# HDSC_HC32L072FAUA register map
Vendor: HDSC Co.Ltd; Series: ARMCM0P; File version: 1.2
CPU: CM0 r0p0, little endian, no MPU, no FPU, 3 interrupt priority bits
Registers are 32-bit, read-write, reset 0x0 unless marked. A register's access mark holds for its fields unless they carry their own. Offsets are from the block's base; [hi:lo] are bit positions; {n}, {i} and the like mark numbered series.

## ADTIM4 — desc ADTIM
Base 0x40003000
Same registers: ADTIM5 0x40003400, ADTIM6 0x40003800
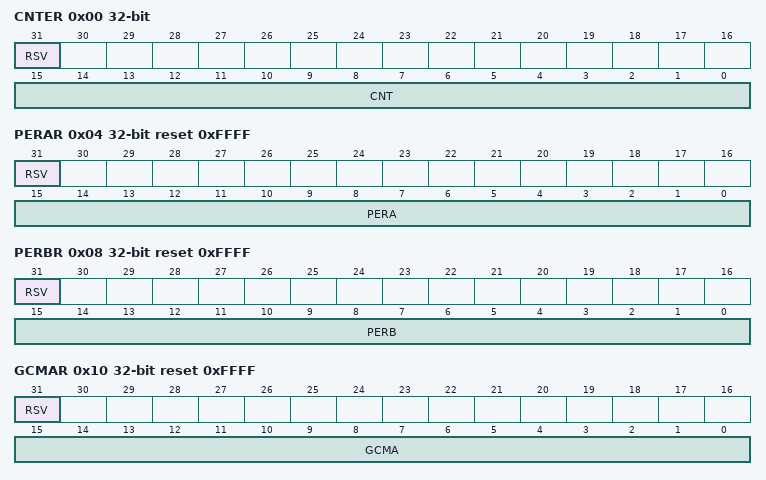
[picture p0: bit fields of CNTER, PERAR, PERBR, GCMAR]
0x00 CNTER (reset mask 0xFFFF)
  [31] RSV, [15:0] CNT
0x04 PERAR reset 0xFFFF (reset mask 0xFFFF)
  [31] RSV, [15:0] PERA
0x08 PERBR reset 0xFFFF (reset mask 0xFFFF)
  [31] RSV, [15:0] PERB
0x10 GCMAR reset 0xFFFF (reset mask 0xFFFF)
  [31] RSV, [15:0] GCMA
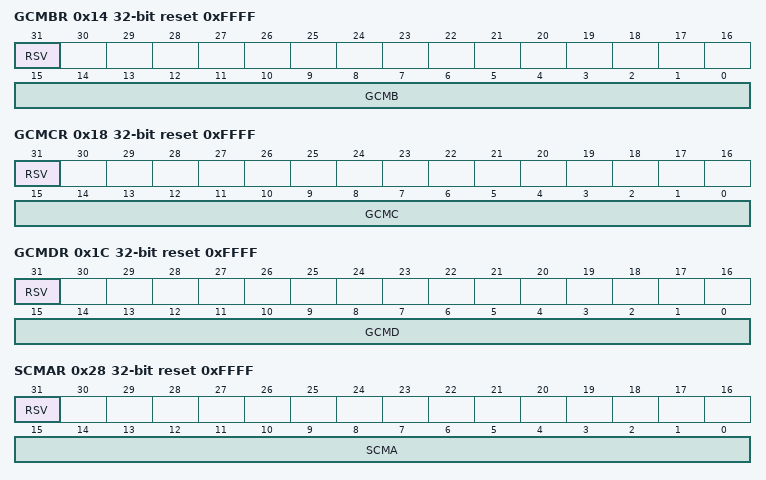
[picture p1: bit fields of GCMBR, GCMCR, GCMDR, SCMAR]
0x14 GCMBR reset 0xFFFF (reset mask 0xFFFF)
  [31] RSV, [15:0] GCMB
0x18 GCMCR reset 0xFFFF (reset mask 0xFFFF)
  [31] RSV, [15:0] GCMC
0x1C GCMDR reset 0xFFFF (reset mask 0xFFFF)
  [31] RSV, [15:0] GCMD
0x28 SCMAR reset 0xFFFF (reset mask 0xFFFF)
  [31] RSV, [15:0] SCMA
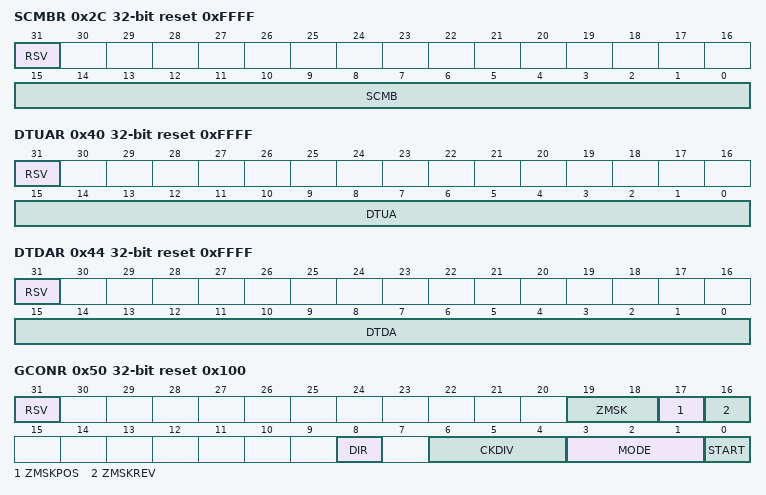
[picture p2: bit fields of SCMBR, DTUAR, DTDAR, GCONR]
0x2C SCMBR reset 0xFFFF (reset mask 0xFFFF)
  [31] RSV, [15:0] SCMB
0x40 DTUAR reset 0xFFFF (reset mask 0xFFFF)
  [31] RSV, [15:0] DTUA
0x44 DTDAR reset 0xFFFF (reset mask 0xFFFF)
  [31] RSV, [15:0] DTDA
0x50 GCONR reset 0x100 (reset mask 0xF017F)
  [31] RSV, [19:18] ZMSK, [17] ZMSKPOS, [16] ZMSKREV, [8] DIR, [6:4] CKDIV, [3:1] MODE, [0] START
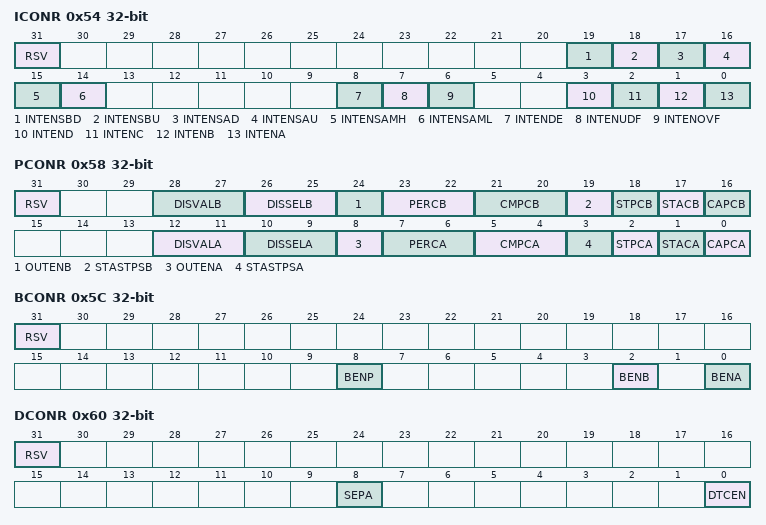
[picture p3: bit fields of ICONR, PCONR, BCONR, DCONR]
0x54 ICONR (reset mask 0xFC1CF)
  [31] RSV, [19] INTENSBD, [18] INTENSBU, [17] INTENSAD, [16] INTENSAU, [15] INTENSAMH, [14] INTENSAML, [8] INTENDE, [7] INTENUDF, [6] INTENOVF, [3] INTEND, [2] INTENC, [1] INTENB, [0] INTENA
0x58 PCONR (reset mask 0x1FFF1FFF)
  [31] RSV, [28:27] DISVALB, [26:25] DISSELB, [24] OUTENB, [23:22] PERCB, [21:20] CMPCB, [19] STASTPSB, [18] STPCB, [17] STACB, [16] CAPCB, [12:11] DISVALA, [10:9] DISSELA, [8] OUTENA, [7:6] PERCA, [5:4] CMPCA, [3] STASTPSA, [2] STPCA, [1] STACA, [0] CAPCA
0x5C BCONR (reset mask 0x105)
  [31] RSV, [8] BENP, [2] BENB, [0] BENA
0x60 DCONR (reset mask 0x101)
  [31] RSV, [8] SEPA, [0] DTCEN
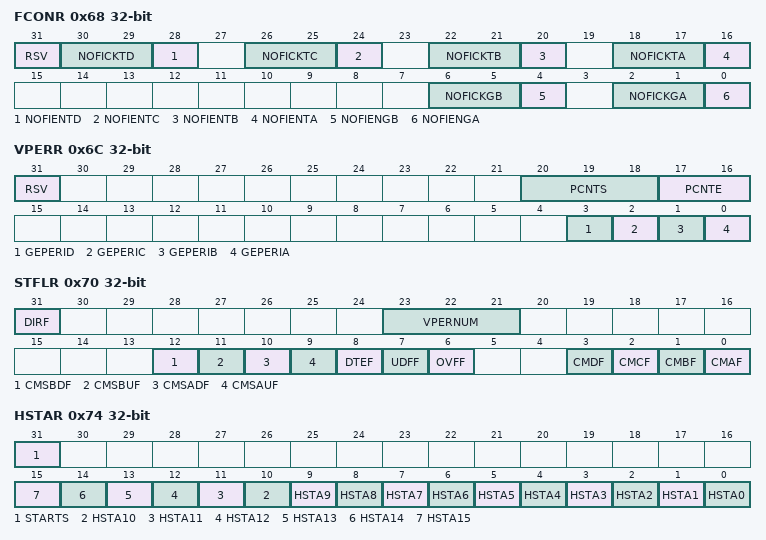
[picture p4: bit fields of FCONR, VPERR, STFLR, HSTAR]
0x68 FCONR (reset mask 0x77770077)
  [31] RSV, [30:29] NOFICKTD, [28] NOFIENTD, [26:25] NOFICKTC, [24] NOFIENTC, [22:21] NOFICKTB, [20] NOFIENTB, [18:17] NOFICKTA, [16] NOFIENTA, [6:5] NOFICKGB, [4] NOFIENGB, [2:1] NOFICKGA, [0] NOFIENGA
0x6C VPERR (reset mask 0x1F000F)
  [31] RSV, [20:18] PCNTS, [17:16] PCNTE, [3] GEPERID, [2] GEPERIC, [1] GEPERIB, [0] GEPERIA
0x70 STFLR
  [31] DIRF ro, [23:21] VPERNUM ro, [12] CMSBDF, [11] CMSBUF, [10] CMSADF, [9] CMSAUF, [8] DTEF, [7] UDFF, [6] OVFF, [3] CMDF, [2] CMCF, [1] CMBF, [0] CMAF
0x74 HSTAR
  [31] STARTS, [n] HSTA{n} (n=0..15)
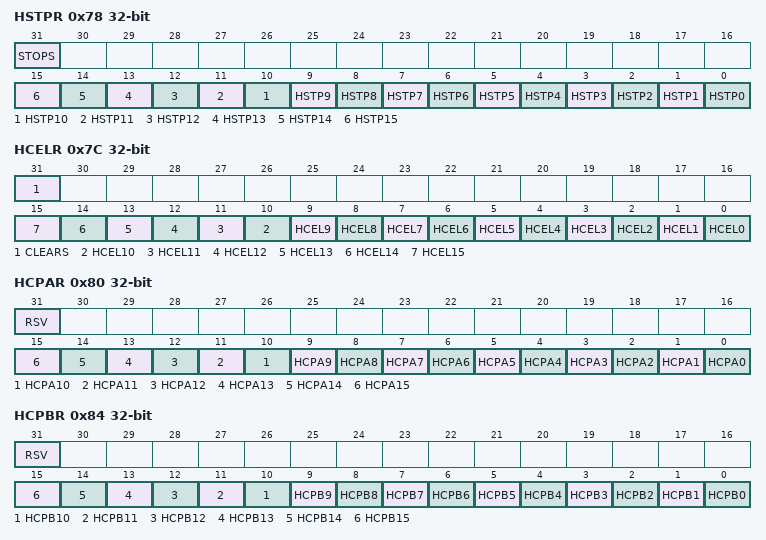
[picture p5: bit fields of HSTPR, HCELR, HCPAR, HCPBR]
0x78 HSTPR
  [31] STOPS, [n] HSTP{n} (n=0..15)
0x7C HCELR
  [31] CLEARS, [n] HCEL{n} (n=0..15)
0x80 HCPAR (reset mask 0xFFFF)
  [31] RSV, [n] HCPA{n} (n=0..15)
0x84 HCPBR (reset mask 0xFFFF)
  [31] RSV, [n] HCPB{n} (n=0..15)
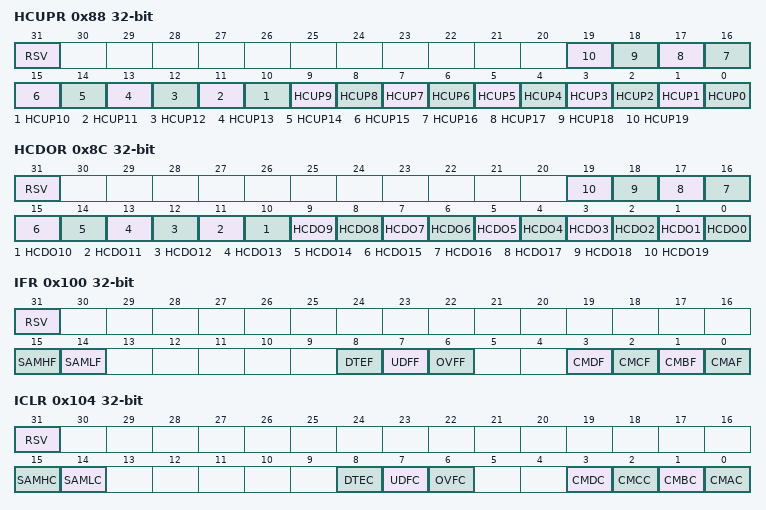
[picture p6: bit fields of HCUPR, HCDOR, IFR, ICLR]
0x88 HCUPR (reset mask 0xFFFFF)
  [31] RSV, [n] HCUP{n} (n=0..19)
0x8C HCDOR (reset mask 0xFFFFF)
  [31] RSV, [n] HCDO{n} (n=0..19)
0x100 IFR ro (reset mask 0xC1CF)
  [31] RSV rw, [15] SAMHF, [14] SAMLF, [8] DTEF, [7] UDFF, [6] OVFF, [3] CMDF, [2] CMCF, [1] CMBF, [0] CMAF
0x104 ICLR wo (reset mask 0xC1CF)
  [31] RSV rw, [15] SAMHC, [14] SAMLC, [8] DTEC, [7] UDFC, [6] OVFC, [3] CMDC, [2] CMCC, [1] CMBC, [0] CMAC
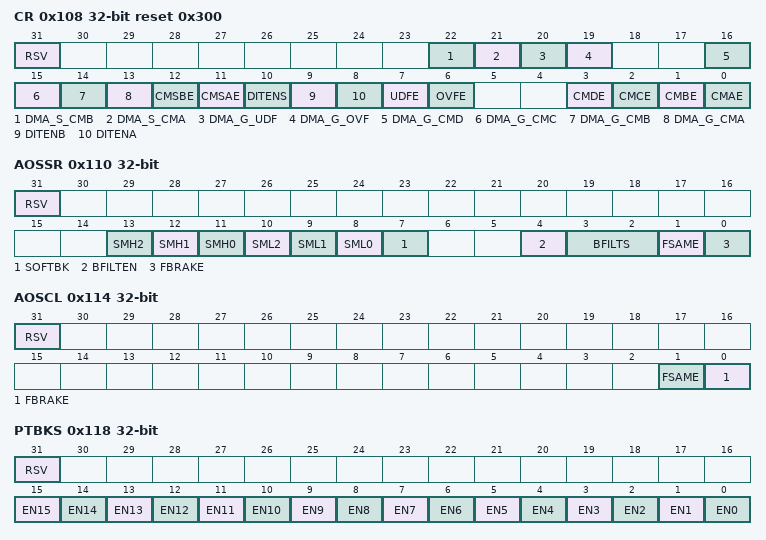
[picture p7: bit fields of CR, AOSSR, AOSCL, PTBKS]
0x108 CR reset 0x300 (reset mask 0x79FFCF)
  [31] RSV, [22] DMA_S_CMB, [21] DMA_S_CMA, [20] DMA_G_UDF, [19] DMA_G_OVF, [16] DMA_G_CMD, [15] DMA_G_CMC, [14] DMA_G_CMB, [13] DMA_G_CMA, [12] CMSBE, [11] CMSAE, [10] DITENS, [9] DITENB, [8] DITENA, [7] UDFE, [6] OVFE, [3] CMDE, [2] CMCE, [1] CMBE, [0] CMAE
0x110 AOSSR (reset mask 0x3F9F)
  [31] RSV, [13] SMH2, [12] SMH1, [11] SMH0, [10] SML2, [9] SML1, [8] SML0, [7] SOFTBK, [4] BFILTEN, [3:2] BFILTS, [1] FSAME ro, [0] FBRAKE ro
0x114 AOSCL wo (reset mask 0x3)
  [31] RSV rw, [1] FSAME, [0] FBRAKE
0x118 PTBKS (reset mask 0xFFFF)
  [31] RSV, [n] EN{n} (n=0..15)
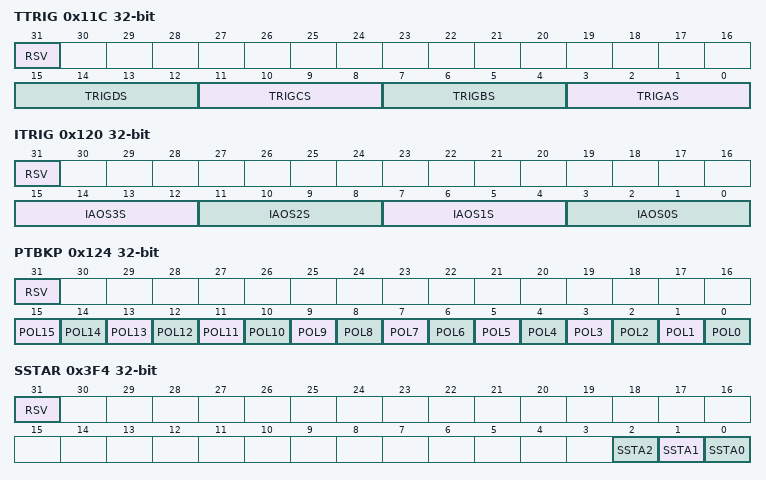
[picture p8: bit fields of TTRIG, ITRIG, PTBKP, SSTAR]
0x11C TTRIG (reset mask 0xFFFF)
  [31] RSV, [15:12] TRIGDS, [11:8] TRIGCS, [7:4] TRIGBS, [3:0] TRIGAS
0x120 ITRIG (reset mask 0xFFFF)
  [31] RSV, [4n+3:4n] IAOS{n}S (n=0..3)
0x124 PTBKP (reset mask 0xFFFF)
  [31] RSV, [n] POL{n} (n=0..15)
0x3F4 SSTAR (reset mask 0x7)
  [31] RSV, [2] SSTA2, [1] SSTA1, [0] SSTA0
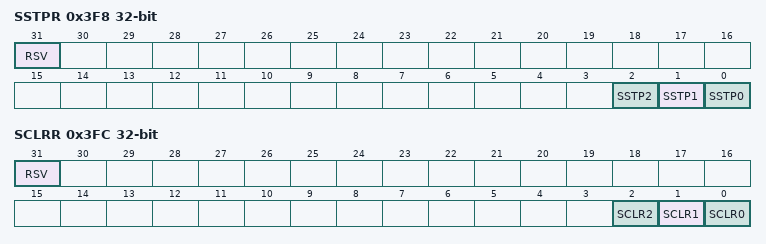
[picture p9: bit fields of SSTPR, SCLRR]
0x3F8 SSTPR (reset mask 0x7)
  [31] RSV, [2] SSTP2, [1] SSTP1, [0] SSTP0
0x3FC SCLRR (reset mask 0x7)
  [31] RSV, [2] SCLR2, [1] SCLR1, [0] SCLR0
